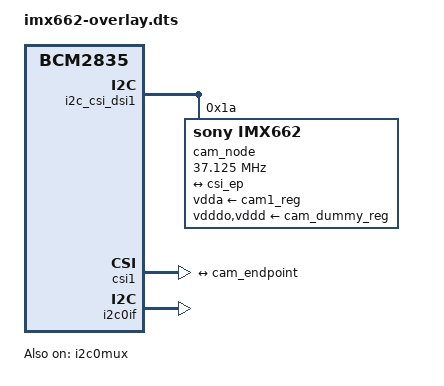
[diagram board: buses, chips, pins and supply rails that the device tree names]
// SPDX-License-Identifier: GPL-2.0-only
// Device Tree Overlay for IMX662 camera module on Raspberry Pi CM5 (BCM2712)
/dts-v1/;
/plugin/;
/ {
	compatible = "brcm,bcm2712", "brcm,bcm2835";
	
	// 保留現有的 fragment 0-3
	fragment@0 {
		target = <&cam_endpoint>;
		__overlay__ {
			data-lanes = <1 2>;
			link-frequencies = /bits/ 64 <594000000>;
		};
	};
	fragment@1 {
		target = <&cam_endpoint>;
		__dormant__ {
			data-lanes = <1 2 3 4>;
			link-frequencies = /bits/ 64 <297000000>;
		};
	};
	fragment@2 {
		target = <&csi_ep>;
		__overlay__ {
			data-lanes = <1 2>;
		};
	};
	fragment@3 {
		target = <&csi_ep>;
		__dormant__ {
			data-lanes = <1 2 3 4>;
		};
	};
	
	i2c_frag: fragment@10 {
		target = <&i2c_csi_dsi1>;  // 變更預設為 CSI1
		__overlay__ {
			#address-cells = <1>;
			#size-cells = <0>;
			status = "okay";
			cam_node: imx662@1a {
				compatible = "sony,imx662";
				reg = <0x1a>;
				clocks = <&cam1_clk>;  // 變更為 cam1_clk
				clock-names = "xclk";
				clock-frequency = <37125000>;
				rotation = <0>;
				orientation = <2>;
				vdda-supply = <&cam1_reg>;  // 變更為 cam1_reg
				vdddo-supply = <&cam_dummy_reg>;
				vddd-supply = <&cam_dummy_reg>;
				port {
					cam_endpoint: endpoint {
						remote-endpoint = <&csi_ep>;
						clock-lanes = <0>;
					};
				};
			};
		};
	};
	
	csi_frag: fragment@11 {
		target = <&csi1>;  // 變更預設為 CSI1
		csi: __overlay__ {
			status = "okay";
			brcm,media-controller;
			port {
				csi_ep: endpoint {
					remote-endpoint = <&cam_endpoint>;
				};
			};
		};
	};
	
	fragment@12 {
		target = <&i2c0if>;
		__overlay__ {
			status = "okay";
		};
	};
	
	clk_frag: fragment@13 {
		target = <&cam1_clk>;  // 變更預設為 cam1_clk
		cam_clk: __overlay__ {
			status = "okay";
			clock-frequency = <37125000>;
		};
	};
	
	fragment@14 {
		target = <&i2c0mux>;
		__overlay__ {
			status = "okay";
		};
	};
	
	__overrides__ {
		4lane = <0>, "-0+1-2+3";
		clock-frequency = <&cam_clk>,"clock-frequency:0",
				  <&cam_node>,"clock-frequency:0";
		rotation = <&cam_node>,"rotation:0";
		orientation = <&cam_node>,"orientation:0";
		media-controller = <&csi>,"brcm,media-controller?";
		
		// 新的 cam0 參數設定
		cam0 = <&i2c_frag>, "target:0=", <&i2c_csi_dsi0>,
			<&csi_frag>, "target:0=", <&csi0>,
			<&clk_frag>, "target:0=", <&cam0_clk>,
			<&cam_node>, "clocks:0=", <&cam0_clk>,
			<&cam_node>, "vdda-supply:0=", <&cam0_reg>;
		
		mono = <0>, "";
	};
};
